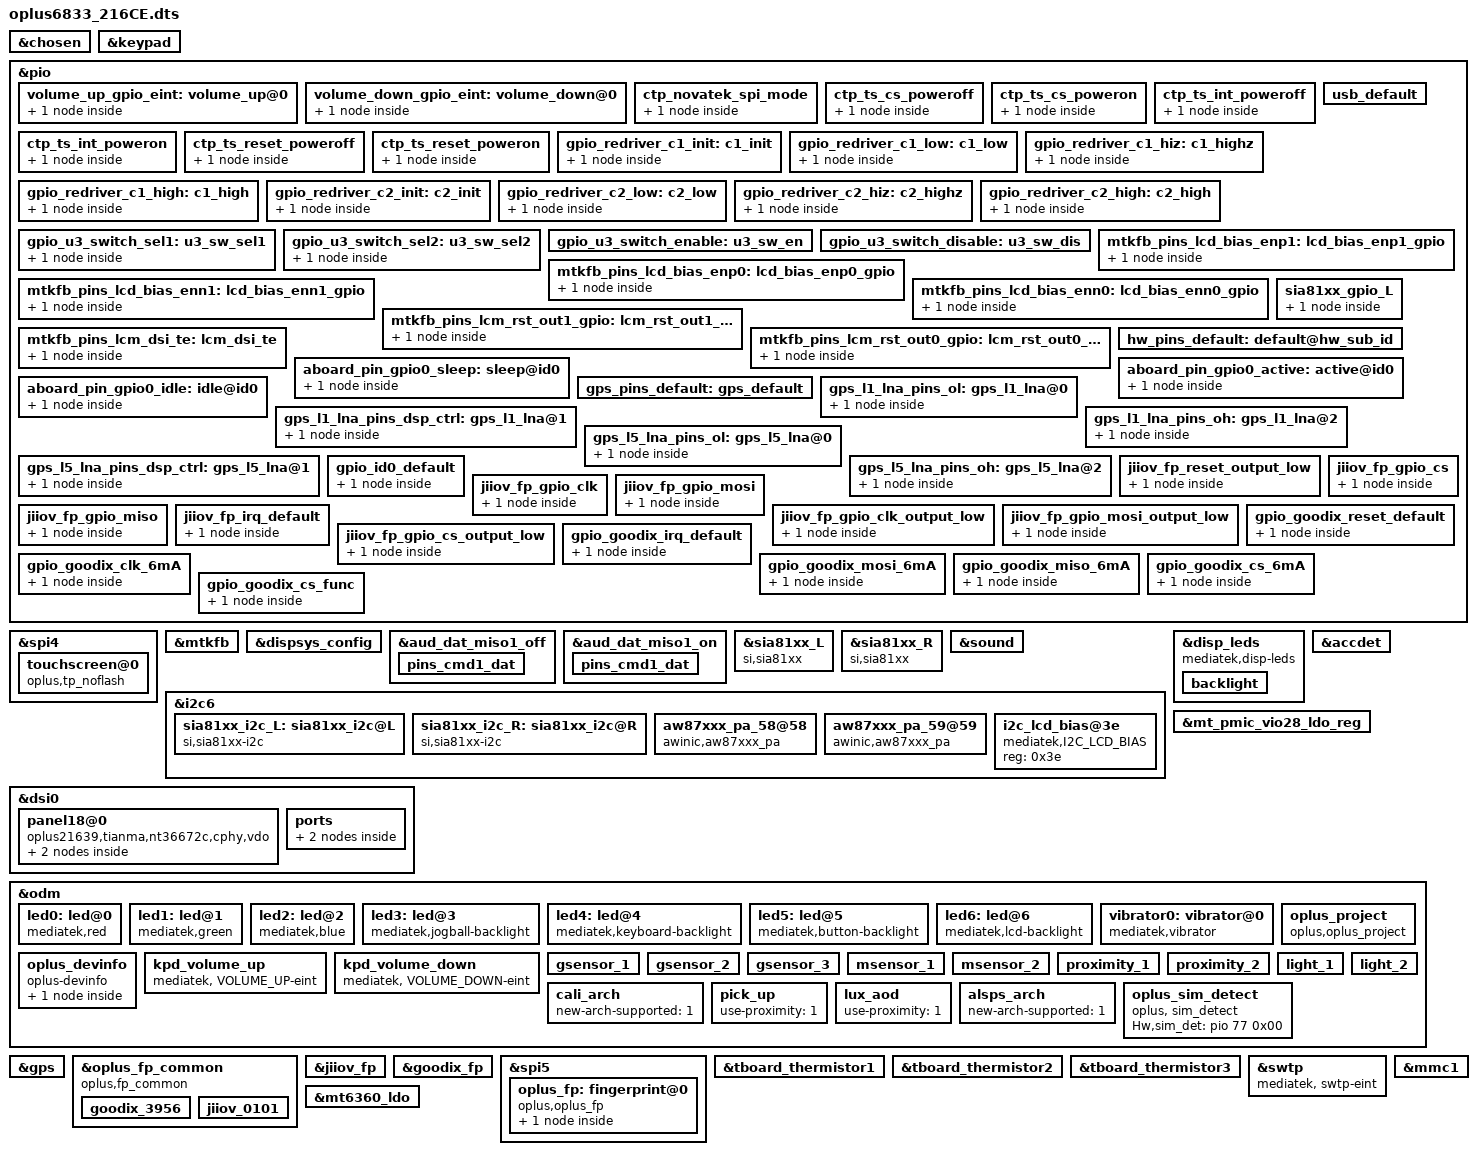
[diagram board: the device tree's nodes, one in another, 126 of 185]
/*
 * Mediatek's mt6833 SoC device tree source
 *
 * Copyright (C) 2016 MediaTek Inc.
 *
 * This program is free software; you can redistribute it and/or modify
 * it under the terms of the GNU General Public License version 2 as
 * published by the Free Software Foundation.
 *
 * This program is distributed in the hope that it will be useful,
 * but WITHOUT ANY WARRANTY; without even the implied warranty of
 * MERCHANTABILITY or FITNESS FOR A PARTICULAR PURPOSE.
 * See http://www.gnu.org/licenses/gpl-2.0.html for more details.
 */
/dts-v1/;
/plugin/;
#include <dt-bindings/interrupt-controller/irq.h>
#include <dt-bindings/interrupt-controller/arm-gic.h>
#ifndef CONFIG_FPGA_EARLY_PORTING
#include <dt-bindings/pinctrl/mt6833-pinfunc.h>
#endif

//#ifdef OPLUS_FEATURE_NFC_BRINGUP
#include "mediatek/nfc/mt6833_alice_pn557.dtsi"
//#endif OPLUS_FEATURE_NFC_BRINGUP

/* chosen */
&chosen {
	atag,videolfb-fb_base_l = <0x7e605000>;
	atag,videolfb-fb_base_h = <0x0>;
	atag,videolfb-islcmfound = <1>;
	atag,videolfb-islcm_inited = <0>;
	atag,videolfb-fps= <6000>;
	atag,videolfb-vramSize= <0x1be0000>;
	atag,videolfb-lcmname=
		"nt35595_fhd_dsi_cmd_truly_nt50358_drv";
};



&keypad {
	keypad,volume-up	= <&pio 1 0x00>;
	keypad,volume-down	= <&pio 80 0x00>;
	pinctrl-names = "volume_up_as_int", "volume_down_as_int";
	pinctrl-0 = <&volume_up_gpio_eint>;
	pinctrl-1 = <&volume_down_gpio_eint>;
	status = "okay";
};
&pio {
	volume_up_gpio_eint:volume_up@0{
		pins_cmd_dat {
			pinmux = <PINMUX_GPIO1__FUNC_GPIO1>;
			slew-rate = <0>;  /*direction 0:in, 1:out*/
			input-enable;
		};
	};

	volume_down_gpio_eint:volume_down@0{
		pins_cmd_dat {
			pinmux = <PINMUX_GPIO80__FUNC_GPIO80>;
			slew-rate = <0>;  /*direction 0:in, 1:out*/
			input-enable;
		};
	};
};

&spi4 {
	status = "okay";

	 touchscreen@0 {
		status = "ok";
		compatible = "oplus,tp_noflash";
		reg = <0>; //Same as CS ID
		chip-name = "NF_NT36672C";
		chip-num = <1>;

		spi-max-frequency = <9600000>;	//4800000,9600000,15000000,19200000
		interrupt-parent = <&pio>;
		interrupts = <14 IRQ_TYPE_EDGE_FALLING 14 0>;
		irq-gpio = <&pio 14 0x2002>;
		reset-gpio = <&pio 15 0>;

		/*driver match info*/
		tp_type = <7>;
		firmware_name = "0xAB417TMNT01";
		platform_support_project = <0x216CE>;
		platform_support_project_dir = <21639>;
		platform_support_project_commandline = "default_commandline";

		/*panel properities*/
		touchpanel,max-num-support = <10>;
		touchpanel,tx-rx-num = <16 36>;
		touchpanel,panel-coords = <1080 2408>;
		touchpanel,display-coords = <1080 2408>;
		touchpanel,touchmajor-limit = <0 216>;

		/*tp-pinctrl*/
		pinctrl-names = "default","pin_set_low", "pin_set_high";
		pinctrl-0 = <&ctp_novatek_spi_mode>;
		pinctrl-1 = <&ctp_ts_cs_poweroff &ctp_ts_int_poweroff &ctp_ts_reset_poweroff>;
		pinctrl-2 = <&ctp_ts_cs_poweron  &ctp_ts_int_poweron  &ctp_ts_reset_poweron>;

		/*sw-feature*/
		incell_screen;
		irq_need_dev_resume_ok;
		fw_edge_limit_support;
		black_gesture_support;
		charger_pump_support;
		headset_pump_support;
		esd_handle_support;
		black_gesture_test_support;
		game_switch_support;
		noflash_support;
		lcd_trigger_load_tp_fw_support;
		smart_gesture_support;
		pressure_report_support;
		fw_update_app_support;
		health_monitor_v2_support;
		//fw_update_in_probe_with_headfile;

		touchpanel,button-type = <4>;
	};
};

&pio {
	ctp_novatek_spi_mode:ctp_novatek_spi_mode{
		pins_cmd_dat {
			pinmux = <PINMUX_GPIO12__FUNC_SPI4_MI>,
				<PINMUX_GPIO13__FUNC_SPI4_MO>,
				<PINMUX_GPIO97__FUNC_SPI4_CLK>,
				<PINMUX_GPIO98__FUNC_SPI4_CSB>;
			drive-strength = <4>;
		};
	};
	ctp_ts_cs_poweroff: ctp_ts_cs_poweroff {
		pins_cmd_dat {
			pinmux = <PINMUX_GPIO98__FUNC_GPIO98>;
			slew-rate = <1>;
			output-low;
			bias-disable;
			//drive-strength = <4>;
		};
	};
	ctp_ts_cs_poweron: ctp_ts_cs_poweron {
		pins_cmd_dat {
			pinmux = <PINMUX_GPIO98__FUNC_SPI4_CSB>;
			drive-strength = <4>;
			//output-high;
		};
	};
	ctp_ts_int_poweroff: ctp_ts_int_poweroff {
		pins_cmd_dat {
			pinmux = <PINMUX_GPIO14__FUNC_GPIO14>;
			slew-rate = <1>;
			output-low;
			bias-disable;
		};
	};
	ctp_ts_int_poweron: ctp_ts_int_poweron {
		pins_cmd_dat {
			pinmux = <PINMUX_GPIO14__FUNC_GPIO14>;
			slew-rate = <0>;
			input-enable;
			bias-pull-up = <00>;
		};
	};
	ctp_ts_reset_poweroff: ctp_ts_reset_poweroff {
		pins_cmd_dat {
			pinmux = <PINMUX_GPIO15__FUNC_GPIO15>;
			slew-rate = <1>;
			output-low;
			bias-disable;
		};
	};

	ctp_ts_reset_poweron: ctp_ts_reset_poweron {
		pins_cmd_dat {
			pinmux = <PINMUX_GPIO15__FUNC_GPIO15>;
			slew-rate = <1>;
			output-high;
			bias-disable;
		};
	};
};

/* USB SWITCH GPIO start */
&pio {
	usb_default: usb_default {
	};

	gpio_redriver_c1_init: c1_init {
		pins_cmd_dat {
			pinmux = <PINMUX_GPIO41__FUNC_GPIO41>;
			slew-rate = <1>;
			output-low;
		};
	};

	gpio_redriver_c1_low: c1_low {
		pins_cmd_dat {
			pinmux = <PINMUX_GPIO41__FUNC_GPIO41>;
			slew-rate = <1>;
			output-low;
		};
	};

	gpio_redriver_c1_hiz: c1_highz {
		pins_cmd_dat {
			pinmux = <PINMUX_GPIO41__FUNC_GPIO41>;
			slew-rate= <0>;
			bias-disable;
		};
	};

	gpio_redriver_c1_high: c1_high {
		pins_cmd_dat {
			pinmux = <PINMUX_GPIO41__FUNC_GPIO41>;
			slew-rate = <1>;
			output-high;
		};
	};

	gpio_redriver_c2_init: c2_init {
		pins_cmd_dat {
			pinmux = <PINMUX_GPIO40__FUNC_GPIO40>;
			slew-rate = <1>;
			output-low;
		};
	};

	gpio_redriver_c2_low: c2_low {
		pins_cmd_dat {
			pinmux = <PINMUX_GPIO40__FUNC_GPIO40>;
			slew-rate = <1>;
			output-low;
		};
	};

	gpio_redriver_c2_hiz: c2_highz {
		pins_cmd_dat {
			pinmux = <PINMUX_GPIO40__FUNC_GPIO40>;
			slew-rate= <0>;
			bias-disable;
		};
	};

	gpio_redriver_c2_high: c2_high {
		pins_cmd_dat {
			pinmux = <PINMUX_GPIO40__FUNC_GPIO40>;
			slew-rate = <1>;
			output-high;
		};
	};

	gpio_u3_switch_sel1: u3_sw_sel1 {
		pins_cmd_dat {
			pinmux = <PINMUX_GPIO11__FUNC_GPIO11>;
			slew-rate = <1>;
			output-low;
		};
	};

	gpio_u3_switch_sel2: u3_sw_sel2 {
		pins_cmd_dat {
			pinmux = <PINMUX_GPIO11__FUNC_GPIO11>;
			slew-rate = <1>;
			output-high;
		};
	};

	gpio_u3_switch_enable: u3_sw_en {
	};

	gpio_u3_switch_disable: u3_sw_dis {
	};
};

#ifndef CONFIG_FPGA_EARLY_PORTING
&pio {
	mtkfb_pins_lcd_bias_enp1: lcd_bias_enp1_gpio {
		pins_cmd_dat {
			pinmux = <PINMUX_GPIO137__FUNC_GPIO137>;
			slew-rate = <1>;
			output-high;
		};
	};

	mtkfb_pins_lcd_bias_enp0: lcd_bias_enp0_gpio {
		pins_cmd_dat {
			pinmux = <PINMUX_GPIO137__FUNC_GPIO137>;
			slew-rate = <1>;
			output-low;
		};
	};

	mtkfb_pins_lcd_bias_enn1: lcd_bias_enn1_gpio {
		pins_cmd_dat {
			pinmux = <PINMUX_GPIO138__FUNC_GPIO138>;
			slew-rate = <1>;
			output-high;
		};
	};

	mtkfb_pins_lcd_bias_enn0: lcd_bias_enn0_gpio {
		pins_cmd_dat {
			pinmux = <PINMUX_GPIO138__FUNC_GPIO138>;
			slew-rate = <1>;
			output-low;
		};
	};

	mtkfb_pins_lcm_rst_out1_gpio: lcm_rst_out1_gpio {
		pins_cmd_dat {
			pinmux = <PINMUX_GPIO86__FUNC_GPIO86>;
			slew-rate = <1>;
			output-high;
		};
	};

	mtkfb_pins_lcm_rst_out0_gpio: lcm_rst_out0_gpio {
		pins_cmd_dat {
			pinmux = <PINMUX_GPIO86__FUNC_GPIO86>;
			slew-rate = <1>;
			output-low;
		};
	};
	mtkfb_pins_lcm_dsi_te: lcm_dsi_te {
		pins_cmd_dat {
			pinmux = <PINMUX_GPIO84__FUNC_DSI_TE>;
		};
	};
};

&mtkfb {
	pinctrl-names = "lcd_bias_enp1_gpio", "lcd_bias_enp0_gpio",
		"lcd_bias_enn1_gpio", "lcd_bias_enn0_gpio",
		"lcm_rst_out1_gpio", "lcm_rst_out0_gpio",
		"mode_te_te";
	pinctrl-0 = <&mtkfb_pins_lcd_bias_enp1>;
	pinctrl-1 = <&mtkfb_pins_lcd_bias_enp0>;
	pinctrl-2 = <&mtkfb_pins_lcd_bias_enn1>;
	pinctrl-3 = <&mtkfb_pins_lcd_bias_enn0>;
	pinctrl-4 = <&mtkfb_pins_lcm_rst_out1_gpio>;
	pinctrl-5 = <&mtkfb_pins_lcm_rst_out0_gpio>;
	pinctrl-6 = <&mtkfb_pins_lcm_dsi_te>;
	status = "okay";
};
&dispsys_config {
	pinctrl-names =
		"lcm_rst_out1_gpio", "lcm_rst_out0_gpio",
		"mode_te_te";
	pinctrl-0 = <&mtkfb_pins_lcm_rst_out1_gpio>;
	pinctrl-1 = <&mtkfb_pins_lcm_rst_out0_gpio>;
	pinctrl-2 = <&mtkfb_pins_lcm_dsi_te>;
	status = "okay";

	helper-value = <0>, /*MTK_DRM_OPT_STAGE*/
		<1>, /*MTK_DRM_OPT_USE_CMDQ*/
		<1>, /*MTK_DRM_OPT_USE_M4U*/
		<0>, /*MTK_DRM_OPT_SODI_SUPPORT*/
		<1>, /*MTK_DRM_OPT_IDLE_MGR*/
		<0>, /*MTK_DRM_OPT_IDLEMGR_SWTCH_DECOUPLE*/
		<0>, /*MTK_DRM_OPT_IDLEMGR_BY_REPAINT*/
		<0>, /*MTK_DRM_OPT_IDLEMGR_ENTER_ULPS*/
		<0>, /*MTK_DRM_OPT_IDLEMGR_KEEP_LP11*/
		<0>, /*MTK_DRM_OPT_DYNAMIC_RDMA_GOLDEN_SETTING*/
		<1>, /*MTK_DRM_OPT_IDLEMGR_DISABLE_ROUTINE_IRQ*/
		<0>, /*MTK_DRM_OPT_MET_LOG*/
		<1>, /*MTK_DRM_OPT_USE_PQ*/
		<1>, /*MTK_DRM_OPT_ESD_CHECK_RECOVERY*/
		<0>, /*MTK_DRM_OPT_ESD_CHECK_SWITCH*/
		<1>, /*MTK_DRM_OPT_PRESENT_FENCE*/
		<0>, /*MTK_DRM_OPT_RDMA_UNDERFLOW_AEE*/
		<1>, /*MTK_DRM_OPT_DSI_UNDERRUN_AEE*/
		<1>, /*MTK_DRM_OPT_HRT*/
		<1>, /*MTK_DRM_OPT_HRT_MODE*/
		<0>, /*MTK_DRM_OPT_DELAYED_TRIGGER*/
		<1>, /*MTK_DRM_OPT_OVL_EXT_LAYER*/
		<0>, /*MTK_DRM_OPT_AOD*/
		<1>, /*MTK_DRM_OPT_RPO*/
		<0>, /*MTK_DRM_OPT_DUAL_PIPE*/
		<0>, /*MTK_DRM_OPT_DC_BY_HRT*/
		<0>, /*MTK_DRM_OPT_OVL_WCG*/
		<0>, /*MTK_DRM_OPT_OVL_SBCH*/
		<1>, /*MTK_DRM_OPT_COMMIT_NO_WAIT_VBLANK*/
		<0>, /*MTK_DRM_OPT_MET*/
		<0>, /*MTK_DRM_OPT_REG_PARSER_RAW_DUMP*/
		<0>, /*MTK_DRM_OPT_VP_PQ*/
		<0>, /*MTK_DRM_OPT_GAME_PQ*/
		<0>, /*MTK_DRM_OPT_MMPATH*/
		<0>, /*MTK_DRM_OPT_HBM*/
		<1>, /*MTK_DRM_OPT_VDS_PATH_SWITCH*/
		<0>, /*MTK_DRM_OPT_LAYER_REC*/
		<1>; /*MTK_DRM_OPT_CLEAR_LAYER*/
};

/* add for dual-mic or singlemic with miso1 */
&aud_dat_miso1_off {
	pins_cmd1_dat {
		pinmux = <PINMUX_GPIO160__FUNC_GPIO160>;
		input-enable;
		bias-pull-down;
	};
};
&aud_dat_miso1_on {
	pins_cmd1_dat {
		pinmux = <PINMUX_GPIO160__FUNC_AUD_DAT_MISO1>;
		input-schmitt-enable;
		bias-disable;
	};
};

&pio {
	sia81xx_gpio_L: sia81xx_gpio_L {
		pins_cmd_dat {
			pinmux = <PINMUX_GPIO63__FUNC_GPIO63>;
			slew-rate = <1>;
			bias-disable;
		};
	};
};

&sia81xx_L {
	compatible = "si,sia81xx";
	si,sia81xx_type = "sia8109";
	si,sia81xx_reset = <&pio 63 0>;
	si,sia81xx_owi = <&pio 63 0>;
	si,sia_boost_vol_support = <1>;
	pinctrl-names = "sia81xx_gpio";
	pinctrl-0 = <&sia81xx_gpio_L>;
	si,sia81xx_disable_pin = <0>;
	/* the same value share a same task
	 * valid value range : 0 ~ 7 */
	timer_task_hdl = <0>;
	channel_num = <0>;
	owi_mode = <1>;
	en_x_filter = <0>;
	en_dynamic_updata_vdd = <1>;
	dynamic_updata_vdd_port = <0x8>;
	algo_is_v2 = <1>;
};

&sia81xx_R {
        compatible = "si,sia81xx";
        si,sia81xx_type = "sia8109";
        si,sia81xx_reset = <&pio 63 0>;
        si,sia81xx_owi = <&pio 63 0>;
        si,sia_boost_vol_support = <1>;
        pinctrl-names = "sia81xx_gpio";
        pinctrl-0 = <&sia81xx_gpio_L>;
        si,sia81xx_disable_pin = <0>;
        /* the same value share a same task
         * valid value range : 0 ~ 7 */
        timer_task_hdl = <0>;
        channel_num = <1>;
        owi_mode = <1>;
        en_x_filter = <0>;
        en_dynamic_updata_vdd = <1>;
        dynamic_updata_vdd_port = <0x8>;
        algo_is_v2 = <1>;
};

&sound {
	/* this dtsi config for product's special config, AudioHal read ctl 'OPLUS_AUDIO_EXTEN_CONFIG' get the values*
	 * 1st value --> PA type: 0:NXP Pa, 1:Awinic Pa 2:sia81xx Pa*/
	audio_extern_config = <2>;
	si,sia81xx-max-num = <2>;
	si,sia81xx-aux-devs = <&sia81xx_L>, <&sia81xx_R>;
	si,sia81xx-aux-devs-prefix = "SpkrLeft", "SpkrRight";
};

&i2c6 {
	sia81xx_i2c_L: sia81xx_i2c@L {
		compatible = "si,sia81xx-i2c";
		reg = <0x28>;
		si,sia81xx-dev = <&sia81xx_L>;
	};

	sia81xx_i2c_R: sia81xx_i2c@R {
		compatible = "si,sia81xx-i2c";
		reg = <0x29>;
		si,sia81xx-dev = <&sia81xx_R>;
	};

	aw87xxx_pa_58@58 {
		compatible = "awinic,aw87xxx_pa";
		reset-gpio = <&pio 131 0>;
		reg = <0x58>;
		pa-channel = < 0 >;
		status = "okay";
	};

	aw87xxx_pa_59@59 {
		compatible = "awinic,aw87xxx_pa";
		reset-gpio = <&pio 139 0>;
		reg = <0x59>;
		pa-channel = < 1 >;
		status = "okay";
	};

       i2c_lcd_bias@3e {
               compatible = "mediatek,I2C_LCD_BIAS";
               reg = <0x3e>;
               status = "okay";
       };
};

&dsi0 {
	status = "okay";
	#address-cells = <1>;
	#size-cells = <0>;
	panel18@0 {
		compatible = "oplus21639,tianma,nt36672c,cphy,vdo";
                reg = <0>;
                reset-gpios = <&pio 86 0>;
		ldo-gpios = <&pio 136 0>;
                bias-gpios = <&pio 137 0>,
                             <&pio 138 0>;
                pinctrl-names = "default";
                port {
                        panel_in18: endpoint {
                                remote-endpoint = <&dsi_out>;
                        };
                };
        };
	ports {
		port {
			dsi_out: endpoint {
				remote-endpoint = <&panel_in18>;
			};
		};
	};
};
#endif

&disp_leds {
	compatible = "mediatek,disp-leds";
        backlight {
                label = "lcd-backlight";
                max-brightness = <4095>;
                led-bits = <12>;
                trans-bits = <12>;
                default-state = "on";
        };
};

#include "mediatek/cust_mt6833_touch_1080x2300.dtsi"
/* accdet start */
&accdet {
	/* accdet micbias voltage: 0x09:2.85v 0x08:2.8v 0x07,
	 * 2.7v;0x05,2.5v;0x02,1.9v
	 */
	accdet-mic-vol = <8>;
	/* accdet pwm_width, pwm_thresh, fall_delay, rise_delay
	 * debounce0, debounce1, debounce3, debounce4
	 * eint pwm_width, eint pwm_thresh
	 * eint deb(debounce0, debounce1, debounce2, debounce3), inv_debounce
	 */
        

	headset-mode-setting = <0x500 0x500 1 0x1f0
				0x1325 0x800 0x3D4 0x44
				0x0 0x7
				0x5 0x9 0x9 0xd 0xe>;
	
	/*headset-mode-setting = <0x500 0x500 1 0x1f0
	*                      0x800 0x800 0x20 0x44
	*                      0x4 0x1
	*                      0x5 0x3 0x3 0x5 0xe>;
	*/
	
	accdet-plugout-debounce = <1>;
	/*1:ACC mode, 2:low cost without in bias, 6:low cost with in bias*/
	accdet-mic-mode = <2>;
	/*0--MD_MAX--UP_MAX--DW_MAX*/
	
	headset-three-key-threshold = <0 82 170 306>;
	
	//headset-three-key-threshold = <0 80 220 400>;
	
	headset-three-key-threshold-CDD = <0 121 192 600>;
	/*0--MD_MAX--VOICE_MAX--UP_MAX--DW_MAX*/
	headset-four-key-threshold = <0 58 121 192 400>;

        
	/* moisture HW mode config start. Enable moisture detection or not
	 * default use HW mode for moisture detection
	 */
	moisture_detect_enable = <1>;
        
	/* select VTH to 2v and 500k, use internal resitance */
	eint_use_ext_res = <0>;
        
	/* enable eint detection mode, if moisture detection enable
	 * eint_detect_mode = moisture_detect_mode;otherwise, select
	 * eint_detect_mode = 4 as DEFAULT
	 */
	eint_detect_mode = <5>;
	/* enable moisture detection mode, if moisture detection enable
	 * eint_detect_mode = moisture_detect_mode
	 */
	moisture_detect_mode = <5>;
	/* select 0: 2.8V; 1: 2.4V; 2: 2V; 3: VTH=MVTH(VTH2) */
	moisture_comp_vth = <2>;
//#ifdef OPLUS_BUG_COMPATIBILITY
	moisture_comp_vref2 = <2>;
//#else
	/* vref2 voltage for different water impedance */
	//moisture_comp_vref2 = <0>;
//#endif
	/* moisture HW mode config end */

	/* moisture SW mode config start, use external resister or not.
	 * DEFAULT NOT NEED
	 */
	moisture_use_ext_res = <0>;
	/* moisture external resister ohm, SW mode by auxadc */
	moisture-external-r = <2000000>;
	/* moisture internal resister ohm, SW mode by auxadc */
	moisture-internal-r = <47000>;
	/* moisture of water resister ohm, SW mode by auxadc*/
	moisture-water-r = <10000>;
	/* moisture SW mode config end */
        //#endif /* VENDOR_EDIT */
	status = "okay";
};
/* accdet end */

&pio {
	hw_pins_default:default@hw_sub_id {
	};
	aboard_pin_gpio0_sleep:sleep@id0 {
		pins_cmd_dat {
			pinmux = <PINMUX_GPIO19__FUNC_GPIO19>;
			slew-rate = <0>;
			bias-pull-down;
			input-enable;
		};
	};

	aboard_pin_gpio0_active:active@id0 {
		pins_cmd_dat {
			pinmux = <PINMUX_GPIO19__FUNC_GPIO19>;
			slew-rate = <0>;
			bias-pull-up;
			input-enable;
		};
	};

	aboard_pin_gpio0_idle:idle@id0 {
		pins_cmd_dat {
			pinmux = <PINMUX_GPIO19__FUNC_GPIO19>;
			slew-rate = <0>;
			bias-disable;
			input-enable;
		};
	};
};
/*#endif OPLUS_FEATURE_TP_BASIC*/

&mt_pmic_vio28_ldo_reg {
	regulator-name = "vio28";
	regulator-min-microvolt = <3000000>;
	regulator-max-microvolt = <3000000>;
	regulator-enable-ramp-delay = <1920>;
};

&odm {
	led0:led@0 {
		compatible = "mediatek,red";
		led_mode = <0>;
		data = <1>;
		pwm_config = <0 0 0 0 0>;
	};
	led1:led@1 {
		compatible = "mediatek,green";
		led_mode = <0>;
		data = <1>;
		pwm_config = <0 0 0 0 0>;
	};
	led2:led@2 {
		compatible = "mediatek,blue";
		led_mode = <0>;
		data = <1>;
		pwm_config = <0 0 0 0 0>;
	};
	led3:led@3 {
		compatible = "mediatek,jogball-backlight";
		led_mode = <0>;
		data = <1>;
		pwm_config = <0 0 0 0 0>;
	};
	led4:led@4 {
		compatible = "mediatek,keyboard-backlight";
		led_mode = <0>;
		data = <1>;
		pwm_config = <0 0 0 0 0>;
	};
	led5:led@5 {
		compatible = "mediatek,button-backlight";
		led_mode = <0>;
		data = <1>;
		pwm_config = <0 0 0 0 0>;
	};
	led6:led@6 {
		compatible = "mediatek,lcd-backlight";
		led_mode = <4>;
		data = <1>;
		pwm_config = <0 1 0 0 0>;
	};
	vibrator0:vibrator@0 {
		compatible = "mediatek,vibrator";
	};
	oplus_project:oplus_project {
		compatible = "oplus,oplus_project";
	};
	oplus_devinfo:oplus_devinfo {
		compatible = "oplus-devinfo";
		pinctrl-names = "default", "aboard_gpio0_sleep", "aboard_gpio0_active", "aboard_gpio0_idle";
		pinctrl-0 = <&hw_pins_default>;
		pinctrl-1 = <&aboard_pin_gpio0_sleep>;
		pinctrl-2 = <&aboard_pin_gpio0_active>;
		pinctrl-3 = <&aboard_pin_gpio0_idle>;
		main-sub {
			use_tristate_gpio;
			compatible = "hw-match, main-sub";
			aboard-gpio0 = <&pio 19 0x00>;
			aboard-patterns = <2>;	/*0[high-resistance] 1[pull-down] 2[pull-up]*/
			/*main board*/
			match-projects = <0x216CE>;
		};
	};
/*#endif OPLUS_FEATURE_TP_BASIC*/

	
	kpd_volume_up:kpd_volume_up {
		compatible = "mediatek, VOLUME_UP-eint";
		interrupt-parent = <&pio>;
		interrupts = <1 IRQ_TYPE_EDGE_FALLING 1 0>;
		debounce = <32000>;
		status = "okay";
	};

	kpd_volume_down:kpd_volume_down {
		compatible = "mediatek, VOLUME_DOWN-eint";
		interrupt-parent = <&pio>;
		interrupts = <80 IRQ_TYPE_EDGE_FALLING 80 0>;
		debounce = <32000>;
		status = "okay";
	};

		/*
		enum {
			LIS3DH,
			LSM6DS3,
			BMI160,
			LIS2HH12,
			LSM6DSM,
			BMI2XY,
			LSM6DSO,
			ICM4X6XX,
			SC7A20,
			BMA4XY,
			BMI3XY,
};
	*/

	gsensor_1: gsensor_1 {
		status = "okay";
		sensor_name = <8>;//SC7A20
		device_name = "sc7a20";
		i2c_num = <2>;
		i2c_addr = <0>;
		direction = <0>;
		eint_num = <3>;
		gyro_cali_version= <2>;
		acc_cali_range= <300 300 300>; //300mg
	};
	gsensor_2: gsensor_2 {
		status = "okay";
		sensor_name = <9>;//BMA4XY
		device_name = "bma4xy";
		i2c_num = <2>;
		i2c_addr = <0>;
		direction = <9>;
		eint_num = <3>;
		gyro_cali_version= <2>;
		acc_cali_range= <300 300 300>; //300mg
	};
	gsensor_3: gsensor_3 {
		status = "okay";
		sensor_name = <10>;//BMI3XY
		device_name = "bmi3xy";
		i2c_num = <2>;
		i2c_addr = <0>;
		direction = <0>;
		eint_num = <3>;
		gyro_cali_version= <2>;
		acc_cali_range= <300 300 300>; //300mg
	};
	/*
	enum {
		AKM09911,
		MMC3530,
		MMC5603,
		MXG4300,
	};
	*/
	msensor_1: msensor_1 {
		status = "okay";
		sensor_name = <2>;//MMC5603
		i2c_num = <0>;
		i2c_addr = <48>;
		direction = <3>;
		eint_num = <0>;
		soft-mag-parameter = <9996 0 2 0 58 1 82 0 9619 0 60 0 188 1 102 0 10628 0>;
	};
	msensor_2: msensor_2 {
		status = "okay";
		sensor_name = <0>;//AKM09911
		i2c_num = <0>;
		i2c_addr = <12>;
		direction = <3>;
		eint_num = <0>;
		soft-mag-parameter = <10255 0 74 1 115 1 163 1 9443 0 161 0 0 0 215 1 10281 0>;
	};
	/*
	enum {
		TMD2725,
		APSD9922,
		STK3335,
		STK3331,
		STK2232,
		TCS3701,
		STK32600,
		STK33502,
		MN78911,
	};
	*/
	proximity_1: proximity_1 {
		status = "okay";
		sensor_name = <7>;//STK33502
		i2c_num = <0>;
		i2c_addr = <0x46>;
		direction = <4>;
		eint_num = <3>;
		low_step = <300>;
		high_step = <400>;
		low_limit = <650>;
		high_limit = <1050>;
		dirty_low_step = <200>;
		dirty_high_step = <300>;
		ps_dirty_limit = <2000>;
		ps_ir_limit = <2000>;
		ps_adjust_min = <0>;
		ps_adjust_max = <1850>;
		sampling_count = <5>;
		step_max = <400>;
		step_min = <100>;
		step_div = <2000>;
		anti_shake_delta = <70>;
		dynamic_cali_max = <5000>;
		raw2offset_radio = <1000>;
		offset_max = <60000>;
		offset_range_min = <0>;
		offset_range_max = <65534>;
		force_cali_limit = <2000>;
		cali_jitter_limit = <30>;
		cal_offset_margin = <3000>;
		sensor-reg = <0x01 0x33>;
		is_use_force_cali = <1>;
	};
	proximity_2: proximity_2 {
		status = "okay";
		sensor_name = <8>;//MN78911
		i2c_num = <0>;
		i2c_addr = <0x41>;
		direction = <4>;
		eint_num = <11>;
		low_step = <300>;
		high_step = <400>;
		low_limit = <650>;
		high_limit = <1050>;
		dirty_low_step = <200>;
		dirty_high_step = <300>;
		ps_dirty_limit = <2000>;
		ps_ir_limit = <2000>;
		ps_adjust_min = <0>;
		ps_adjust_max = <1850>;
		sampling_count = <5>;
		step_max = <400>;
		step_min = <100>;
		step_div = <2000>;
		anti_shake_delta = <70>;
		dynamic_cali_max = <5000>;
		raw2offset_radio = <1000>;
		offset_max = <60000>;
		offset_range_min = <0>;
		offset_range_max = <65534>;
		force_cali_limit = <2000>;
		cali_jitter_limit = <30>;
		cal_offset_margin = <120>;
		is_use_force_cali = <1>;
	};
	light_1: light_1 {
		status = "okay";
		sensor_name = <7>;//STK33502
		i2c_num = <0>;
		i2c_addr = <0x46>;
		direction = <4>;
		eint_num = <3>;
		als_buffer_length =<8>;
		als_ratio = <90>;
		als_type = <1>;//<1-normal;2-under screen;3-normal needed compensation>
		device_name = "stk33502";
		als_spectral_coefficient = <1>;
		coefficient_mode = <6>; //6x coefficient mode
		als_coef_a = <8500>; //*100
		als_coef_b = <39500>; //*100
		als_coef_c = <4300>; //*100
		als_coef_d = <14300>; //*100
		als_coef_e = <10000>; //*100
		als_coef_ratio = <70>;
	};
	light_2: light_2 {
		status = "okay";
		sensor_name = <8>;//MN78911
		i2c_num = <0>;
		i2c_addr = <0x41>;
		direction = <4>;
		eint_num = <11>;
		als_type = <1>;//<1-normal;2-under screen;3-normal needed compensation>
		als_buffer_length = <10>;
		offset_gain = <510>;
		scale_gain = <655>;
		offset_gain_2 = <122>;
		scale_gain_2 = <283>;
		cwf_ratio_thd = <400>;
		d65_ratio_thd = <1000>;
		a_ratio_thd = <1700>;
		d65_factor = <740>;
		a_factor = <1000>;
		hz_factor = <1000>;
		lux_revocer = <480>;
		als_ratio = <78>;
		lsrc_algr_way = <1>;
		lsrc_coe = <737>;
		als_max_lux_condiition = <12000>;
		low_lux_h_thd = <160>;
		low_lux_l_thd = <60>;
		low_lux_ext = <0>;
		low_lux_ratio = <1250>;
	};
	cali_arch: cali_arch {
		status = "okay";
		new-arch-supported = <1>;
	};
	pick_up: pick_up {
		status = "okay";
		use-proximity = <1>;
	};
	lux_aod: lux_aod {
		status = "okay";
		use-proximity = <1>;
	};
	alsps_arch: alsps_arch {
		status = "okay";
		new-arch-supported = <1>;
	};
//#ifdef OPLUS_FEATURE_TP_BASIC
    oplus_sim_detect {
        compatible = "oplus, sim_detect";
        Hw,sim_det = <&pio 77 0x00>;
    };
//#endif /* OPLUS_FEATURE_TP_BASIC */
};

/* GPS GPIO standardization start */
&pio {
	gps_pins_default: gps_default {
	};

	gps_l1_lna_pins_ol: gps_l1_lna@0 {
		pins_cmd_dat {
			pinmux = <PINMUX_GPIO65__FUNC_GPIO65>;
			output-low;
		};
	};
	gps_l1_lna_pins_dsp_ctrl: gps_l1_lna@1 {
		pins_cmd_dat {
			pinmux = <PINMUX_GPIO65__FUNC_GPS_L1_ELNA_EN>;
		};
	};
	gps_l1_lna_pins_oh: gps_l1_lna@2 {
		pins_cmd_dat {
			pinmux = <PINMUX_GPIO65__FUNC_GPIO65>;
			output-high;
		};
	};

	gps_l5_lna_pins_ol: gps_l5_lna@0 {
		pins_cmd_dat {
			pinmux = <PINMUX_GPIO91__FUNC_GPIO91>;
			output-low;
		};
	};
	gps_l5_lna_pins_dsp_ctrl: gps_l5_lna@1 {
		pins_cmd_dat {
			pinmux = <PINMUX_GPIO91__FUNC_GPS_L5_ELNA_EN>;
		};
	};
	gps_l5_lna_pins_oh: gps_l5_lna@2 {
		pins_cmd_dat {
			pinmux = <PINMUX_GPIO91__FUNC_GPIO91>;
			output-high;
		};
	};
};

&gps {
	pinctrl-names = "default",
		"gps_l1_lna_disable",
		"gps_l1_lna_dsp_ctrl",
		"gps_l1_lna_enable",
		"gps_l5_lna_disable",
		"gps_l5_lna_dsp_ctrl",
		"gps_l5_lna_enable";
	pinctrl-0 = <&gps_pins_default>;
	pinctrl-1 = <&gps_l1_lna_pins_ol>;
	pinctrl-2 = <&gps_l1_lna_pins_dsp_ctrl>;
	pinctrl-3 = <&gps_l1_lna_pins_oh>;
	pinctrl-4 = <&gps_l5_lna_pins_ol>;
	pinctrl-5 = <&gps_l5_lna_pins_dsp_ctrl>;
	pinctrl-6 = <&gps_l5_lna_pins_oh>;
	status = "okay";
};
/* GPS GPIO standardization end */

//#ifdef OPLUS_FEATURE_FINGERPRINT
&oplus_fp_common {
	compatible = "oplus,fp_common"; //Manufacture, and Model
	oplus,fp_gpio_num = <1>;
	oplus,fp_gpio_0 = <&pio 140 0x00>;
	goodix_3956 {
		oplus,fp-id = <1>; /* fp id mapping table */
		vendor-chip = <27>; /* please refer to the struct fp_vendor_t in oplus_fp_commmon.n */
		eng-menu = "-1,-1"; /* represents SNR, inclination test item in engineer menu, and 0/1 means off/on */
		chip-name = "G_3956";  /* /proc/fp_id, will be displayed in engineer menu  */
	};
	jiiov_0101{
		oplus,fp-id = <0>; /* fp id mapping table */
		vendor-chip = <31>; /* please refer to the struct fp_vendor_t in oplus_fp_commmon.h */
		eng-menu = "-1,-1"; /* represents SNR, inclination test item in engineer menu, and 0/1 means off/on */
		chip-name = "JIIOV_0101";  /* /proc/fp_id, will be displayed in engineer menu  */
	};
};

&pio{
	gpio_id0_default: gpio_id0_default {
		pins_cmd_dat {
			pinmux = <PINMUX_GPIO140__FUNC_GPIO140>;
			slew-rate = <0>;
			bias-pull-up = <00>;
			input-enable;
		};
	};
};
&jiiov_fp {
	anc,gpio_irq = <&pio 22 0x00>;
	anc,gpio_rst = <&pio 21 0x00>;
	ldo-supply = <&mt_pmic_vfp_ldo_reg>;
	pinctrl-names = "anc_reset_default", "anc_irq_default", "anc_spi_active", "anc_spi_output_low";
	pinctrl-0 = <&jiiov_fp_reset_output_low>;
	pinctrl-1 = <&jiiov_fp_irq_default>;
    pinctrl-2 = <&jiiov_fp_gpio_clk>, <&jiiov_fp_gpio_mosi>, <&jiiov_fp_gpio_miso>, <&jiiov_fp_gpio_cs>;
	pinctrl-3 = <&jiiov_fp_gpio_clk_output_low>, <&jiiov_fp_gpio_mosi_output_low>, <&jiiov_fp_gpio_cs_output_low>;
	status = "okay";
};

&pio{
jiiov_fp_reset_output_low: jiiov_fp_reset_output_low {
				pins_cmd_dat {
					pinmux = <PINMUX_GPIO21__FUNC_GPIO21>;
					slew-rate = <1>;
					output-low;
				};
			};
jiiov_fp_gpio_clk: jiiov_fp_gpio_clk {
				pins_cmd_dat {
					pinmux = <PINMUX_GPIO35__FUNC_SPI5_CLK>;
					drive-strength = <2>;
				};
			};
jiiov_fp_gpio_mosi: jiiov_fp_gpio_mosi {
				pins_cmd_dat {
					pinmux = <PINMUX_GPIO37__FUNC_SPI5_MO>;
					drive-strength = <2>;
				};
			};
jiiov_fp_gpio_miso: jiiov_fp_gpio_miso {
				pins_cmd_dat {
					pinmux = <PINMUX_GPIO38__FUNC_SPI5_MI>;
					drive-strength = <3>;
				};
			};
jiiov_fp_gpio_cs: jiiov_fp_gpio_cs {
				pins_cmd_dat {
					pinmux = <PINMUX_GPIO36__FUNC_SPI5_CSB>;
					drive-strength = <2>;
				};
			};
jiiov_fp_irq_default: jiiov_fp_irq_default {
				pins_cmd_dat {
					pinmux = <PINMUX_GPIO22__FUNC_GPIO22>;
					slew-rate = <0>;
					input-enable;
					bias-pull-down;
				};
			};
jiiov_fp_gpio_clk_output_low: jiiov_fp_gpio_clk_output_low {
				pins_cmd_dat {
					pinmux = <PINMUX_GPIO35__FUNC_GPIO35>;
					slew-rate = <1>;
					output-low;
				};
			};
jiiov_fp_gpio_mosi_output_low: jiiov_fp_gpio_mosi_output_low {
				pins_cmd_dat {
					pinmux = <PINMUX_GPIO37__FUNC_GPIO37>;
					slew-rate = <1>;
					output-low;
                    		};
                	};
jiiov_fp_gpio_cs_output_low: jiiov_fp_gpio_cs_output_low {
				pins_cmd_dat {
					pinmux = <PINMUX_GPIO36__FUNC_GPIO36>;
					slew-rate = <1>;
					output-low;
				};
			};
};

&goodix_fp {
	goodix,gpio_irq = <&pio 22 0x00>;
	goodix,gpio_reset = <&pio 21 0x00>;
	goodix,gpio_cs = <&pio 36 0x00>;
	pinctrl-names = "default", "gf_spi_drive_6mA", "gf_cs_func","goodix_irq_no_pull";
	pinctrl-0 = <&gpio_goodix_irq_default>, <&gpio_goodix_reset_default>;
	pinctrl-1 = <&gpio_goodix_clk_6mA>, <&gpio_goodix_mosi_6mA>, <&gpio_goodix_miso_6mA>, <&gpio_goodix_cs_6mA>;
	pinctrl-2 = <&gpio_goodix_cs_func>;
	status = "okay";
};

&pio{
gpio_goodix_reset_default: gpio_goodix_reset_default {
				pins_cmd_dat {
					pinmux = <PINMUX_GPIO21__FUNC_GPIO21>;
					slew-rate = <1>;
					output-low;
				};
			};
gpio_goodix_irq_default: gpio_goodix_irq_default {
				pins_cmd_dat {
					pinmux = <PINMUX_GPIO22__FUNC_GPIO22>;
					slew-rate = <0>;
					bias-pull-down;
				};
			};
gpio_goodix_clk_6mA: gpio_goodix_clk_6mA {
			     pins_cmd_dat {
				     pinmux = <PINMUX_GPIO35__FUNC_SPI5_CLK>;
				     drive-strength = <2>;
			     };
		     };
gpio_goodix_mosi_6mA: gpio_goodix_mosi_6mA {
			      pins_cmd_dat {
				      pinmux = <PINMUX_GPIO37__FUNC_SPI5_MO>;
				      drive-strength = <2>;
			      };
		      };
gpio_goodix_miso_6mA: gpio_goodix_miso_6mA {
			      pins_cmd_dat {
				      pinmux = <PINMUX_GPIO38__FUNC_SPI5_MI>;
				      drive-strength = <3>;
			      };
		      };
gpio_goodix_cs_6mA: gpio_goodix_cs_6mA {
			    pins_cmd_dat {
				    pinmux = <PINMUX_GPIO36__FUNC_SPI5_CSB>;
				    drive-strength = <2>;
			    };
		    };
gpio_goodix_cs_func: gpio_goodix_cs_func {
			     pins_cmd_dat {
				     pinmux = <PINMUX_GPIO36__FUNC_SPI5_CSB>;
				     drive-strength = <2>;
			     };
		     };
};

&spi5 {
#address-cells = <1>;
#size-cells = <0>;
status = "okay";
oplus_fp: fingerprint@0 {
		 compatible = "oplus,oplus_fp";
		 reg = <0>;
		 spi-max-frequency = <8000000>;
		 spi-id = <5>;
		 spi-irq = <39>;
		 spi-reg = <11019000>;
		 dvdd-supply = <&mt_pmic_vfp_ldo_reg>;
		 dvdd-config = <3000000 3000000 150000>;
		 power-num = <1>;
		 status = "okay";
		 power_source_1 {
			 power-mode = <1>;
			 power-name = "dvdd";
			 power-config = "dvdd-config";
			 delay-time = <0>;
		 };
	 };
};
/* FINGERPRINT end */
//#endif /*OPLUS_FEATURE_FINGERPRINT*/

/*bts*/
&tboard_thermistor1{
		 oplus,ntc_cust_support = <1>;
		 oplus,ntc_pull_up_r = <100000>;
};
/*btsmdpa*/
&tboard_thermistor2{
		 oplus,ntc_cust_support = <1>;
		 oplus,ntc_pull_up_r = <100000>;
};
/*btsnrpa*/
&tboard_thermistor3{
		 oplus,ntc_cust_support = <1>;
		 oplus,ntc_pull_up_r = <100000>;
};
//#ifdef OPLUS_VENDOR_SWTP
&swtp {
    compatible = "mediatek, swtp-eint";
};
//#endif  /*OPLUS_VENDOR_SWTP*/
//#endif /* OPLUS_FEATURE_FINGERPRINT */
#include "mediatek/cust_mt6833_camera_21639.dtsi"
#include <oplus6833_216CE/cust.dtsi>
//#include "mediatek/cust_mt6833_nfc_20796.dtsi"

//#ifdef OPLUS_FEATURE_CHG_BASIC
#include "mediatek/oplus_charge_mt6833_21639.dtsi"
//#endif

&mmc1 {
    cd-gpios = <&pio 4 0>;
    status = "okay";
    vmmc-supply = <&mt_pmic_vmch_ldo_reg>;
};
&mt6360_ldo {
	sdcard_det_en = <1>;
	sdcard_hlact = <0>;
};

/*End of this file, DO NOT ADD ANYTHING HERE*/
